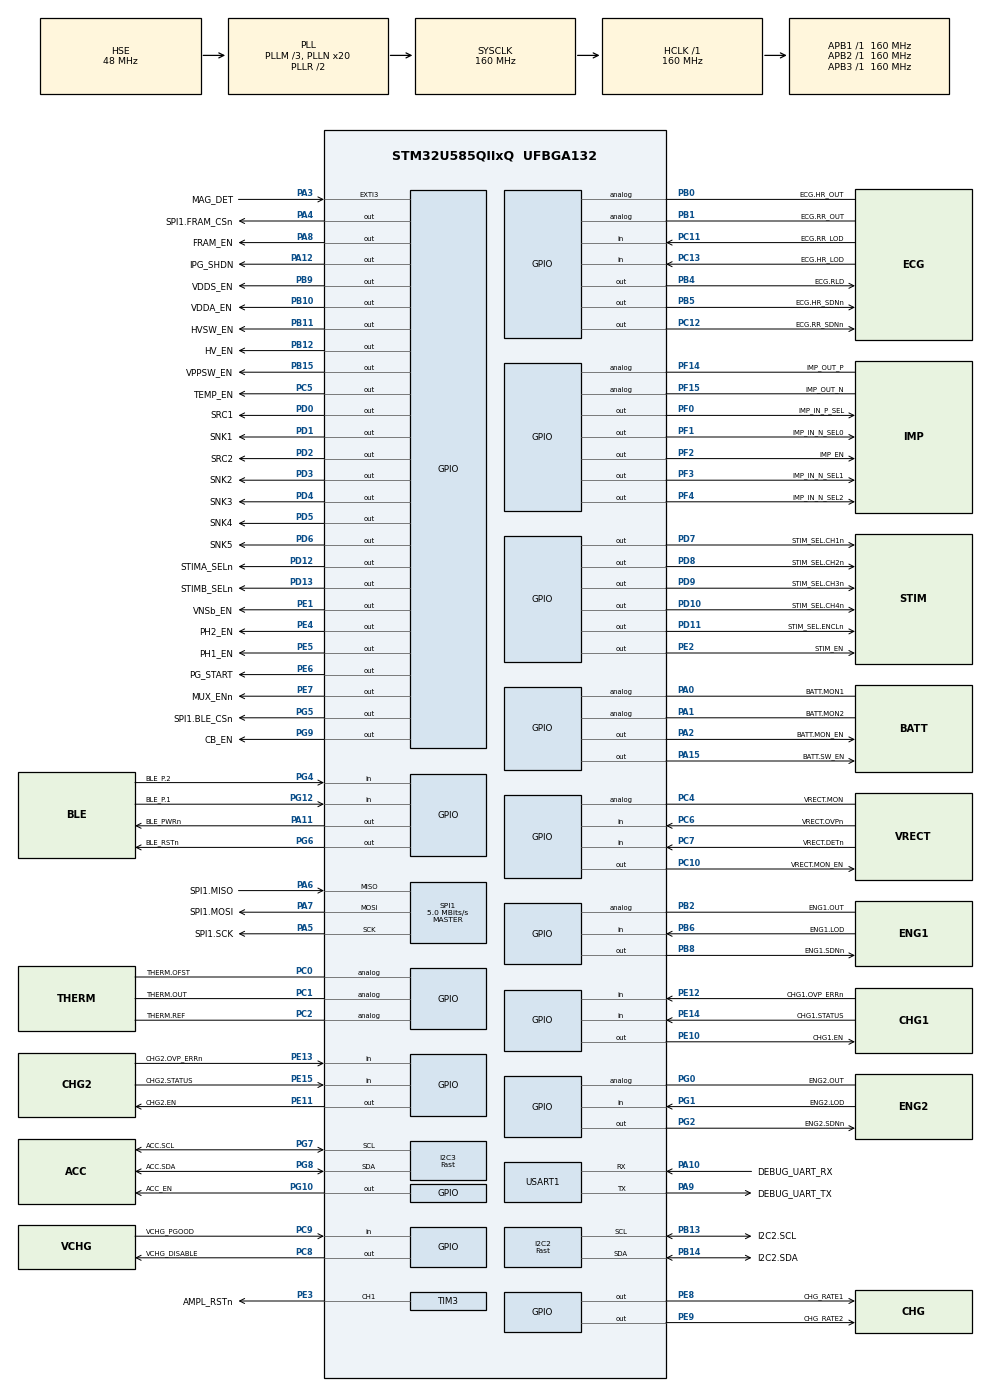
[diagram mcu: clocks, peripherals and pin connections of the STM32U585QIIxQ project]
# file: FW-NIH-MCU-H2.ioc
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ADC1.Channel-0\#ChannelRegularConversion=ADC_CHANNEL_VREFINT
ADC1.Channel-10\#ChannelRegularConversion=ADC_CHANNEL_VREFINT
ADC1.ClockPrescaler=ADC_CLOCK_ASYNC_DIV2
ADC1.ContinuousConvMode=DISABLE
ADC1.ConversionDataManagement=ADC_CONVERSIONDATA_DMA_ONESHOT
ADC1.DiscontinuousConvMode=DISABLE
ADC1.EOCSelection=ADC_EOC_SINGLE_CONV
ADC1.EnableInjectedConversion=DISABLE
ADC1.EnableRegularConversion=ENABLE
ADC1.ExternalTrigConv=ADC_EXTERNALTRIG_T6_TRGO
ADC1.MonitoredBy-0\#ChannelRegularConversion=__NULL
ADC1.MonitoredBy-10\#ChannelRegularConversion=__NULL
ADC1.NbrOfConversion=2
ADC1.NbrOfConversionFlag=1
ADC1.OffsetNumber-0\#ChannelRegularConversion=ADC_OFFSET_NONE
ADC1.OffsetNumber-10\#ChannelRegularConversion=ADC_OFFSET_NONE
ADC1.Rank-0\#ChannelRegularConversion=1
ADC1.Rank-10\#ChannelRegularConversion=2
ADC1.Resolution=ADC_RESOLUTION_12B
ADC1.SamplingTime-0\#ChannelRegularConversion=ADC_SAMPLETIME_5CYCLE
ADC1.SamplingTime-10\#ChannelRegularConversion=ADC_SAMPLETIME_5CYCLE
ADC1.master=1
ADC4.Channel1=true
ADC4.Channell1=false
ADC4.ClockPrescaler=ADC_CLOCK_ASYNC_DIV2
ADC4.ContinuousConvMode=DISABLE
ADC4.EOCSelection=ADC_EOC_SINGLE_CONV
ADC4.ExternalTrigConv=ADC4_EXTERNALTRIG_T15_TRGO
ADC4.NbrOfConversion=1
ADC4.NbrOfConversionFlag=0
ADC4.SamplingTimeCommon1=ADC4_SAMPLETIME_7CYCLES_5
ADC4.SamplingTimeCommon2=ADC4_SAMPLETIME_1CYCLE_5
ADC4.SelectedChannel=ADC_CHANNEL_VREFINT
CORTEX_M33_NS.userName=CORTEX_M33
CRC.CRCLength=CRC_POLYLENGTH_16B
CRC.DefaultInitValueUse=DEFAULT_INIT_VALUE_DISABLE
CRC.DefaultPolynomialUse=DEFAULT_POLYNOMIAL_DISABLE
CRC.GeneratingPolynomial=X12+X5+X0
CRC.InitValue=0xFFFF
GPDMA1.CIRCULARMODE_GPDMACH0=DISABLE
GPDMA1.CIRCULARMODE_GPDMACH1=DISABLE
GPDMA1.DESTDATAWIDTH_GPDMACH0=DMA_DEST_DATAWIDTH_WORD
GPDMA1.DESTDATAWIDTH_GPDMACH1=DMA_DEST_DATAWIDTH_WORD
GPDMA1.DESTINC_GPDMACH0=DMA_DINC_INCREMENTED
GPDMA1.DESTINC_GPDMACH1=DMA_DINC_INCREMENTED
GPDMA1.IPHANDLE_GPDMACH0-SIMPLEREQUEST_GPDMACH0=__NULL
GPDMA1.IPHANDLE_GPDMACH1-SIMPLEREQUEST_GPDMACH1=__NULL
GPDMA1.LINKALLOCATEDPORT_CIRCULAR_GPDMACH1=DMA_LINK_ALLOCATED_PORT1
GPDMA1.REQUEST_GPDMACH0=GPDMA1_REQUEST_ADC1
GPDMA1.REQUEST_GPDMACH1=GPDMA1_REQUEST_ADC4
GPDMA1.SRCDATAWIDTH_GPDMACH0=DMA_SRC_DATAWIDTH_WORD
GPDMA1.SRCDATAWIDTH_GPDMACH1=DMA_SRC_DATAWIDTH_WORD
GPDMA1.TRANSFERALLOCATEDPORTDEST_GPDMACH1=DMA_DEST_ALLOCATED_PORT1
GPDMA1.TRANSFERALLOCATEDPORTSRC_GPDMACH1=DMA_SRC_ALLOCATED_PORT1
HASH.DataType=HASH_DATATYPE_8B
HASH.SecureHashAlgorithmType=SHA256
I2C2.I2C_Speed_Mode=I2C_Fast
I2C2.Timing=0x00F07BFF
I2C3.I2C_Coeff_DF=0
I2C3.I2C_Speed_Mode=I2C_Fast
I2C3.Timing=0x00F07BFF
IWDG.EWI=100
IWDG.Prescaler=IWDG_PRESCALER_32
IWDG.Reload=1000
IWDG.Window=4095
LPTIM1.ClockPrescaler=LPTIM_PRESCALER_DIV128
LPTIM1.Period=60*256
LPTIM1.RepetitionCounter=60-1
LPTIM1.UpdateMode=LPTIM_UPDATE_ENDOFPERIOD
LPTIM2.ClockPrescaler=LPTIM_PRESCALER_DIV128
LPTIM2.Period=1*256
LPTIM2.RepetitionCounter=1-1
LPTIM2.UpdateMode=LPTIM_UPDATE_ENDOFPERIOD
LPTIM3.ClockPrescaler=LPTIM_PRESCALER_DIV128
LPTIM3.Period=60*256
LPTIM3.RepetitionCounter=1-1
LPTIM4.ClockPrescaler=LPTIM_PRESCALER_DIV128
LPTIM4.Period=256/2
LPTIM4.RepetitionCounter=1-1
Mcu.Family=STM32U5
Mcu.Name=STM32U585QIIxQ
Mcu.Package=UFBGA132
NVIC.ADC1_IRQn=true\:0\:0\:false\:false\:true\:true\:true\:true
NVIC.ADC4_IRQn=true\:0\:0\:false\:false\:true\:true\:true\:true
NVIC.EXTI3_IRQn=true\:0\:0\:false\:false\:true\:true\:true\:true
NVIC.GPDMA1_Channel0_IRQn=true\:0\:0\:false\:false\:true\:false\:true\:true
NVIC.GPDMA1_Channel1_IRQn=true\:0\:0\:false\:false\:true\:false\:true\:true
NVIC.HASH_IRQn=true\:0\:0\:false\:false\:true\:true\:true\:true
NVIC.I2C2_ER_IRQn=true\:0\:0\:false\:false\:true\:true\:true\:true
NVIC.I2C2_EV_IRQn=true\:0\:0\:false\:false\:true\:true\:true\:true
NVIC.I2C3_ER_IRQn=true\:0\:0\:false\:false\:true\:true\:true\:true
NVIC.I2C3_EV_IRQn=true\:0\:0\:false\:false\:true\:true\:true\:true
NVIC.ICACHE_IRQn=true\:0\:0\:false\:false\:true\:true\:true\:true
NVIC.IWDG_IRQn=true\:0\:0\:false\:false\:true\:true\:true\:true
NVIC.LPTIM1_IRQn=true\:0\:0\:false\:false\:true\:true\:true\:true
NVIC.LPTIM2_IRQn=true\:0\:0\:false\:false\:true\:true\:true\:true
NVIC.LPTIM3_IRQn=true\:0\:0\:false\:false\:true\:true\:true\:true
NVIC.LPTIM4_IRQn=true\:0\:0\:false\:false\:true\:true\:true\:true
NVIC.PKA_IRQn=true\:0\:0\:false\:false\:true\:true\:true\:true
NVIC.PriorityGroup=NVIC_PRIORITYGROUP_4
NVIC.RNG_IRQn=true\:0\:0\:false\:false\:true\:true\:true\:true
NVIC.RTC_IRQn=true\:0\:0\:false\:false\:true\:true\:true\:true
NVIC.SPI1_IRQn=true\:0\:0\:false\:false\:true\:true\:true\:true
NVIC.TIM15_IRQn=true\:0\:0\:false\:false\:true\:true\:true\:true
NVIC.TIM3_IRQn=true\:0\:0\:true\:false\:true\:true\:true\:true
NVIC.TIM4_IRQn=true\:0\:0\:false\:false\:true\:true\:true\:true
NVIC.TIM5_IRQn=true\:0\:0\:false\:false\:true\:true\:true\:true
NVIC.TIM6_IRQn=true\:0\:0\:false\:false\:true\:true\:true\:true
NVIC.USART1_IRQn=true\:0\:0\:false\:false\:true\:true\:true\:true
PA0.GPIO_Label=BATT.MON1
PA0.Signal=SharedAnalog_PA0
PA1.GPIO_Label=BATT.MON2
PA1.Signal=SharedAnalog_PA1
PA10.GPIO_Label=DEBUG_UART_RX
PA10.Mode=Asynchronous
PA10.Signal=USART1_RX
PA11.GPIO_Label=BLE_PWRn
PA11.GPIO_PuPd=GPIO_NOPULL
PA11.GPIO_Speed=GPIO_SPEED_FREQ_VERY_HIGH
PA11.PinState=GPIO_PIN_SET
PA11.Signal=GPIO_Output
PA12.GPIO_Label=IPG_SHDN
PA12.Signal=GPIO_Output
PA13\ (JTMS/SWDIO).GPIO_Label=SWDIO
PA13\ (JTMS/SWDIO).Mode=Trace_Asynchronous_SW
PA13\ (JTMS/SWDIO).Signal=DEBUG_JTMS-SWDIO
PA14\ (JTCK/SWCLK).GPIO_Label=SWCLK
PA14\ (JTCK/SWCLK).Mode=Trace_Asynchronous_SW
PA14\ (JTCK/SWCLK).Signal=DEBUG_JTCK-SWCLK
PA15\ (JTDI).GPIO_Label=BATT.SW_EN 
PA15\ (JTDI).GPIO_PuPd=GPIO_PULLUP
PA15\ (JTDI).PinState=GPIO_PIN_SET
PA15\ (JTDI).Signal=GPIO_Output
PA2.GPIO_Label=BATT.MON_EN
PA2.Signal=GPIO_Output
PA3.GPIO_Label=MAG_DET
PA3.GPIO_ModeDefaultEXTI=GPIO_MODE_IT_RISING_FALLING
PA3.Signal=GPXTI3
PA4.GPIO_Label=SPI1.FRAM_CSn
PA4.Signal=GPIO_Output
PA5.GPIO_Label=SPI1.SCK
PA5.Mode=Full_Duplex_Master
PA5.Signal=SPI1_SCK
PA6.GPIO_Label=SPI1.MISO 
PA6.Mode=Full_Duplex_Master
PA6.Signal=SPI1_MISO
PA7.GPIO_Label=SPI1.MOSI
PA7.Mode=Full_Duplex_Master
PA7.Signal=SPI1_MOSI
PA8.GPIO_Label=FRAM_EN
PA8.GPIO_PuPd=GPIO_PULLUP
PA8.GPIO_Speed=GPIO_SPEED_FREQ_VERY_HIGH
PA8.Signal=GPIO_Output
PA9.GPIO_Label=DEBUG_UART_TX
PA9.Mode=Asynchronous
PA9.Signal=USART1_TX
PB0.GPIO_Label=ECG.HR_OUT
PB0.Signal=SharedAnalog_PB0
PB1.GPIO_Label=ECG.RR_OUT
PB1.Signal=SharedAnalog_PB1
PB10.GPIO_Label=VDDA_EN
PB10.Signal=GPIO_Output
PB11.GPIO_Label=HVSW_EN
PB11.Signal=GPIO_Output
PB12.GPIO_Label=HV_EN
PB12.Signal=GPIO_Output
PB13.GPIO_Label=I2C2.SCL
PB13.GPIO_Pu=GPIO_PULLUP
PB13.GPIO_Speed=GPIO_SPEED_FREQ_LOW
PB13.Mode=I2C
PB13.Signal=I2C2_SCL
PB14.GPIO_Label=I2C2.SDA
PB14.GPIO_Pu=GPIO_PULLUP
PB14.GPIO_Speed=GPIO_SPEED_FREQ_LOW
PB14.Mode=I2C
PB14.Signal=I2C2_SDA
PB15.GPIO_Label=VPPSW_EN
PB15.Signal=GPIO_Output
PB2.GPIO_Label=ENG1.OUT
PB2.Signal=SharedAnalog_PB2
PB3\ (JTDO/TRACESWO).GPIO_Label=SWO
PB3\ (JTDO/TRACESWO).Mode=Trace_Asynchronous_SW
PB3\ (JTDO/TRACESWO).Signal=DEBUG_JTDO-SWO
PB4\ (NJTRST).GPIO_Label=ECG.RLD
PB4\ (NJTRST).Signal=GPIO_Output
PB5.GPIO_Label=ECG.HR_SDNn
PB5.Signal=GPIO_Output
PB6.GPIO_Label=ENG1.LOD
PB6.GPIO_PuPd=GPIO_PULLUP
PB6.Signal=GPIO_Input
PB8.GPIO_Label=ENG1.SDNn
PB8.Signal=GPIO_Output
PB9.GPIO_Label=VDDS_EN
PB9.Signal=GPIO_Output
PC0.GPIO_Label=THERM.OFST
PC0.Signal=SharedAnalog_PC0
PC1.GPIO_Label=THERM.OUT
PC1.Signal=SharedAnalog_PC1
PC10.GPIO_Label=VRECT.MON_EN
PC10.Signal=GPIO_Output
PC11.GPIO_Label=ECG.RR_LOD
PC11.GPIO_PuPd=GPIO_PULLUP
PC11.Signal=GPIO_Input
PC12.GPIO_Label=ECG.RR_SDNn
PC12.Signal=GPIO_Output
PC13.GPIO_Label=ECG.HR_LOD
PC13.GPIO_PuPd=GPIO_PULLUP
PC13.Signal=GPIO_Input
PC14-OSC32_IN\ (PC14).Mode=LSE-External-Oscillator
PC14-OSC32_IN\ (PC14).Signal=RCC_OSC32_IN
PC15-OSC32_OUT\ (PC15).Mode=LSE-External-Oscillator
PC15-OSC32_OUT\ (PC15).Signal=RCC_OSC32_OUT
PC2.GPIO_Label=THERM.REF
PC2.Signal=SharedAnalog_PC2
PC4.GPIO_Label=VRECT.MON
PC4.Signal=SharedAnalog_PC4
PC5.GPIO_Label=TEMP_EN
PC5.Signal=GPIO_Output
PC6.GPIO_Label=VRECT.OVPn
PC6.GPIO_PuPd=GPIO_PULLUP
PC6.Signal=GPIO_Input
PC7.GPIO_Label=VRECT.DETn
PC7.GPIO_PuPd=GPIO_PULLUP
PC7.Signal=GPIO_Input
PC8.GPIO_Label=VCHG_DISABLE
PC8.Signal=GPIO_Output
PC9.GPIO_Label=VCHG_PGOOD
PC9.Signal=GPIO_Input
PD0.GPIO_Label=SRC1
PD0.GPIO_PuPd=GPIO_PULLUP
PD0.GPIO_Speed=GPIO_SPEED_FREQ_VERY_HIGH
PD0.Signal=GPIO_Output
PD1.GPIO_Label=SNK1
PD1.GPIO_PuPd=GPIO_PULLUP
PD1.GPIO_Speed=GPIO_SPEED_FREQ_VERY_HIGH
PD1.Signal=GPIO_Output
PD10.GPIO_Label=STIM_SEL.CH4n
PD10.GPIO_PuPd=GPIO_PULLUP
PD10.GPIO_Speed=GPIO_SPEED_FREQ_VERY_HIGH
PD10.Signal=GPIO_Output
PD11.GPIO_Label=STIM_SEL.ENCLn
PD11.GPIO_PuPd=GPIO_PULLUP
PD11.GPIO_Speed=GPIO_SPEED_FREQ_VERY_HIGH
PD11.Signal=GPIO_Output
PD12.GPIO_Label=STIMA_SELn
PD12.GPIO_PuPd=GPIO_PULLUP
PD12.GPIO_Speed=GPIO_SPEED_FREQ_VERY_HIGH
PD12.Signal=GPIO_Output
PD13.GPIO_Label=STIMB_SELn
PD13.GPIO_PuPd=GPIO_PULLUP
PD13.GPIO_Speed=GPIO_SPEED_FREQ_VERY_HIGH
PD13.Signal=GPIO_Output
PD2.GPIO_Label=SRC2
PD2.GPIO_PuPd=GPIO_PULLUP
PD2.GPIO_Speed=GPIO_SPEED_FREQ_VERY_HIGH
PD2.Signal=GPIO_Output
PD3.GPIO_Label=SNK2
PD3.GPIO_PuPd=GPIO_PULLUP
PD3.GPIO_Speed=GPIO_SPEED_FREQ_VERY_HIGH
PD3.Signal=GPIO_Output
PD4.GPIO_Label=SNK3
PD4.GPIO_PuPd=GPIO_PULLUP
PD4.GPIO_Speed=GPIO_SPEED_FREQ_VERY_HIGH
PD4.Signal=GPIO_Output
PD5.GPIO_Label=SNK4
PD5.GPIO_PuPd=GPIO_PULLUP
PD5.GPIO_Speed=GPIO_SPEED_FREQ_VERY_HIGH
PD5.Signal=GPIO_Output
PD6.GPIO_Label=SNK5
PD6.GPIO_PuPd=GPIO_PULLUP
PD6.GPIO_Speed=GPIO_SPEED_FREQ_VERY_HIGH
PD6.Signal=GPIO_Output
PD7.GPIO_Label=STIM_SEL.CH1n
PD7.GPIO_PuPd=GPIO_PULLUP
PD7.GPIO_Speed=GPIO_SPEED_FREQ_VERY_HIGH
PD7.Signal=GPIO_Output
PD8.GPIO_Label=STIM_SEL.CH2n
PD8.GPIO_PuPd=GPIO_PULLUP
PD8.GPIO_Speed=GPIO_SPEED_FREQ_VERY_HIGH
PD8.Signal=GPIO_Output
PD9.GPIO_Label=STIM_SEL.CH3n
PD9.GPIO_PuPd=GPIO_PULLUP
PD9.GPIO_Speed=GPIO_SPEED_FREQ_VERY_HIGH
PD9.Signal=GPIO_Output
PE1.GPIO_Label=VNSb_EN
PE1.GPIO_PuPd=GPIO_PULLUP
PE1.Signal=GPIO_Output
PE10.GPIO_Label=CHG1.EN 
PE10.Signal=GPIO_Output
PE11.GPIO_Label=CHG2.EN 
PE11.Signal=GPIO_Output
PE12.GPIO_Label=CHG1.OVP_ERRn
PE12.GPIO_PuPd=GPIO_PULLUP
PE12.Signal=GPIO_Input
PE13.GPIO_Label=CHG2.OVP_ERRn
PE13.GPIO_PuPd=GPIO_PULLUP
PE13.Signal=GPIO_Input
PE14.GPIO_Label=CHG1.STATUS
PE14.GPIO_PuPd=GPIO_PULLUP
PE14.Signal=GPIO_Input
PE15.GPIO_Label=CHG2.STATUS 
PE15.GPIO_PuPd=GPIO_PULLUP
PE15.Signal=GPIO_Input
PE2.GPIO_Label=STIM_EN
PE2.GPIO_PuPd=GPIO_PULLUP
PE2.Signal=GPIO_Output
PE3.GPIO_Label=AMPL_RSTn
PE3.GPIO_PuPd=GPIO_PULLUP
PE3.GPIO_Speed=GPIO_SPEED_FREQ_VERY_HIGH
PE3.Signal=S_TIM3_CH1
PE4.GPIO_Label=PH2_EN
PE4.GPIO_PuPd=GPIO_NOPULL
PE4.Signal=GPIO_Output
PE5.GPIO_Label=PH1_EN
PE5.GPIO_PuPd=GPIO_NOPULL
PE5.PinState=GPIO_PIN_SET
PE5.Signal=GPIO_Output
PE6.GPIO_Label=PG_START
PE6.GPIO_PuPd=GPIO_NOPULL
PE6.PinState=GPIO_PIN_SET
PE6.Signal=GPIO_Output
PE7.GPIO_Label=MUX_ENn
PE7.Signal=GPIO_Output
PE8.GPIO_Label=CHG_RATE1
PE8.Signal=GPIO_Output
PE9.GPIO_Label=CHG_RATE2
PE9.Signal=GPIO_Output
PF0.GPIO_Label=IMP_IN_P_SEL
PF0.GPIO_PuPd=GPIO_PULLUP
PF0.GPIO_Speed=GPIO_SPEED_FREQ_VERY_HIGH
PF0.Signal=GPIO_Output
PF1.GPIO_Label=IMP_IN_N_SEL0
PF1.GPIO_PuPd=GPIO_PULLUP
PF1.GPIO_Speed=GPIO_SPEED_FREQ_VERY_HIGH
PF1.Signal=GPIO_Output
PF14.GPIO_Label=IMP_OUT_P
PF14.Signal=SharedAnalog_PF14
PF15.GPIO_Label=IMP_OUT_N
PF15.Signal=SharedAnalog_PF15
PF2.GPIO_Label=IMP_EN
PF2.GPIO_PuPd=GPIO_PULLUP
PF2.GPIO_Speed=GPIO_SPEED_FREQ_LOW
PF2.Signal=GPIO_Output
PF3.GPIO_Label=IMP_IN_N_SEL1
PF3.GPIO_PuPd=GPIO_PULLUP
PF3.GPIO_Speed=GPIO_SPEED_FREQ_VERY_HIGH
PF3.Signal=GPIO_Output
PF4.GPIO_Label=IMP_IN_N_SEL2
PF4.GPIO_PuPd=GPIO_PULLUP
PF4.GPIO_Speed=GPIO_SPEED_FREQ_VERY_HIGH
PF4.Signal=GPIO_Output
PG0.GPIO_Label=ENG2.OUT
PG0.Signal=SharedAnalog_PG0
PG1.GPIO_Label=ENG2.LOD
PG1.GPIO_PuPd=GPIO_PULLUP
PG1.Signal=GPIO_Input
PG10.GPIO_Label=ACC_EN
PG10.Signal=GPIO_Output
PG12.GPIO_Label=BLE_P.1
PG12.GPIO_PuPd=GPIO_PULLUP
PG12.Signal=GPIO_Input
PG2.GPIO_Label=ENG2.SDNn
PG2.Signal=GPIO_Output
PG4.GPIO_Label=BLE_P.2
PG4.GPIO_PuPd=GPIO_PULLUP
PG4.Signal=GPIO_Input
PG5.GPIO_Label=SPI1.BLE_CSn
PG5.Signal=GPIO_Output
PG6.GPIO_Label=BLE_RSTn
PG6.GPIO_ModeDefaultOutputPP=GPIO_MODE_OUTPUT_OD
PG6.GPIO_PuPd=GPIO_NOPULL
PG6.Signal=GPIO_Output
PG7.GPIO_Label=ACC.SCL
PG7.GPIO_Speed=GPIO_SPEED_FREQ_VERY_HIGH
PG7.Mode=I2C
PG7.Signal=I2C3_SCL
PG8.GPIO_Label=ACC.SDA
PG8.GPIO_Speed=GPIO_SPEED_FREQ_VERY_HIGH
PG8.Mode=I2C
PG8.Signal=I2C3_SDA
PG9.GPIO_Label=CB_EN
PG9.PinState=GPIO_PIN_SET
PG9.Signal=GPIO_Output
PH0-OSC_IN\ (PH0).Mode=HSE-External-Oscillator
PH0-OSC_IN\ (PH0).Signal=RCC_OSC_IN
PH1-OSC_OUT\ (PH1).Mode=HSE-External-Oscillator
PH1-OSC_OUT\ (PH1).Signal=RCC_OSC_OUT
PWR.PowerMode=PWR_SMPS_SUPPLY
PWR.pwrPrivilege=PWR_PRIVILEGE_NO
ProjectManager.HeapSize=0x200
ProjectManager.StackSize=0x400
ProjectManager.TargetToolchain=STM32CubeIDE
RCC.ADCCLockSelection=RCC_ADCDACCLKSOURCE_PLL2
RCC.ADCFreq_Value=10000000
RCC.AHBFreq_Value=160000000
RCC.APB1Freq_Value=160000000
RCC.APB1TimFreq_Value=160000000
RCC.APB2Freq_Value=160000000
RCC.APB2TimFreq_Value=160000000
RCC.APB3Freq_Value=160000000
RCC.CortexFreq_Value=160000000
RCC.EPOD_VALUE=48000000
RCC.HCLKFreq_Value=160000000
RCC.HSE_VALUE=48000000
RCC.HSI48_VALUE=48000000
RCC.HSI_VALUE=16000000
RCC.LPTIM1CLockSelectionVirtual=RCC_LPTIM1CLKSOURCE_LSE
RCC.LPTIM2CLockSelectionVirtual=RCC_LPTIM2CLKSOURCE_LSE
RCC.LPTIM3CLockSelectionVirtual=RCC_LPTIM34CLKSOURCE_LSE
RCC.LSIDIV_VALUE=32000
RCC.MSI_VALUE=4000000
RCC.PLL2M=12
RCC.PLL2N=40
RCC.PLL2R=16
RCC.PLL2Source=RCC_PLLSOURCE_HSE
RCC.PLLM=3
RCC.PLLN=20
RCC.PLLSourceVirtual=RCC_PLLSOURCE_HSE
RCC.RTCClockSelection=RCC_RTCCLKSOURCE_LSE
RCC.SYSCLKFreq_VALUE=160000000
RCC.SYSCLKSource=RCC_SYSCLKSOURCE_PLLCLK
RCC.USBFreq_Value=48000000
RCC.VCOOutputFreq_Value=320000000
RTC.WakeUpAutoClr=0
RTC.WakeUpClock-WakeUp=RTC_WAKEUPCLOCK_CK_SPRE_16BITS
RTC.WakeUpCounter-WakeUp=60-1
RTC.WeekDay=RTC_WEEKDAY_SUNDAY
RTC.Year=23
SH.S_TIM3_CH1.0=TIM3_CH1,PWM Generation1 CH1
SH.SharedAnalog_PA0.0=GPIO_Analog
SH.SharedAnalog_PA0.1=ADC1_IN5
SH.SharedAnalog_PA1.0=GPIO_Analog
SH.SharedAnalog_PA1.1=ADC1_IN6
SH.SharedAnalog_PB0.0=GPIO_Analog
SH.SharedAnalog_PB0.1=ADC1_IN15
SH.SharedAnalog_PB1.0=GPIO_Analog
SH.SharedAnalog_PB1.1=ADC1_IN16
SH.SharedAnalog_PB2.0=GPIO_Analog
SH.SharedAnalog_PB2.1=ADC1_IN17
SH.SharedAnalog_PC0.0=GPIO_Analog
SH.SharedAnalog_PC0.1=ADC4_IN1
SH.SharedAnalog_PC1.0=GPIO_Analog
SH.SharedAnalog_PC1.1=ADC4_IN2
SH.SharedAnalog_PC2.0=GPIO_Analog
SH.SharedAnalog_PC2.1=ADC4_IN3
SH.SharedAnalog_PC4.0=GPIO_Analog
SH.SharedAnalog_PC4.1=ADC4_IN22
SH.SharedAnalog_PF14.0=GPIO_Analog
SH.SharedAnalog_PF14.1=ADC4_IN5
SH.SharedAnalog_PF15.0=GPIO_Analog
SH.SharedAnalog_PF15.1=ADC4_IN6
SH.SharedAnalog_PG0.0=GPIO_Analog
SH.SharedAnalog_PG0.1=ADC4_IN7
SPI1.BaudRatePrescaler=SPI_BAUDRATEPRESCALER_32
SPI1.CalculateBaudRate=5.0 MBits/s
SPI1.DataSize=SPI_DATASIZE_8BIT
SPI1.Direction=SPI_DIRECTION_2LINES
SPI1.Mode=SPI_MODE_MASTER
SPI1.VirtualType=VM_MASTER
TIM15.PeriodNoDither=1000-1
TIM15.Prescaler=16-1
TIM15.TIM_MasterOutputTrigger=TIM_TRGO_UPDATE
TIM3.Channel-Output\ Compare2\ No\ Output=TIM_CHANNEL_2
TIM3.Channel-PWM\ Generation1\ CH1=TIM_CHANNEL_1
TIM3.OC1Preload_PWM=ENABLE
TIM3.OC2Preload=ENABLE
TIM3.OCMode_2=TIM_OCMODE_TOGGLE
TIM3.PeriodNoDither=1000-1
TIM3.Prescaler=160-1
TIM3.PulseNoDither_1=100-1
TIM3.PulseNoDither_2=1
TIM4.Channel-Output\ Compare2\ No\ Output=TIM_CHANNEL_2
TIM4.Channel-PWM\ Generation1\ No\ Output=TIM_CHANNEL_1
TIM4.OC1Preload_PWM=ENABLE
TIM4.OC2Preload=DISABLE
TIM4.OCMode_2=TIM_OCMODE_TOGGLE
TIM4.PeriodNoDither=1000-1
TIM4.Prescaler=160-1
TIM4.PulseNoDither_1=100-1
TIM4.PulseNoDither_2=1
TIM5.Channel-Output\ Compare2\ No\ Output=TIM_CHANNEL_2
TIM5.Channel-PWM\ Generation1\ No\ Output=TIM_CHANNEL_1
TIM5.OC1Preload_PWM=ENABLE
TIM5.OC2Preload=ENABLE
TIM5.OCMode_2=TIM_OCMODE_TOGGLE
TIM5.PeriodNoDither=1000-1
TIM5.Prescaler=160-1
TIM5.PulseNoDither_1=100-1
TIM5.PulseNoDither_2=1
TIM6.PeriodNoDither=1000-1
TIM6.Prescaler=16-1
TIM6.TIM_MasterOutputTrigger=TIM_TRGO_UPDATE
USART1.VirtualMode-Asynchronous=VM_ASYNC
VP_ADC1_Vref_Input.Mode=IN-Vrefint
VP_ADC4_Vref_Input.Mode=IN-Vrefint
VP_CRC_VS_CRC.Mode=CRC_Activate
VP_GPDMA1_VS_GPDMACH0.Mode=SIMPLEREQUEST_GPDMACH0
VP_GPDMA1_VS_GPDMACH1.Mode=SIMPLEREQUEST_GPDMACH1
VP_HASH_VS_HASH.Mode=HASH_Activate
VP_ICACHE_VS_ICACHE.Mode=DefaultMode
VP_IWDG_VS_IWDG.Mode=IWDG_Activate
VP_LPBAMQUEUE_VS_QUEUE.Mode=QUEUEMODE
VP_LPBAM_VS_SIG1.Mode=SmartRun
VP_LPBAM_VS_SIG4.Mode=LPDMA1
VP_LPTIM1_VS_LPTIM_counterModeInternalClock.Mode=Counts__internal_clock_event_00
VP_LPTIM2_VS_LPTIM_counterModeInternalClock.Mode=Counts__internal_clock_event_00
VP_LPTIM3_VS_LPTIM_counterModeInternalClock.Mode=Counts__internal_clock_event_00
VP_LPTIM4_VS_LPTIM_counterModeInternalClock.Mode=Counts__internal_clock_event_00
VP_MEMORYMAP_VS_MEMORYMAP.Mode=CurAppReg
VP_PKA_VS_PKA.Mode=PKA_Activate
VP_PWR_VS_DBSignals.Mode=DisableDeadBatterySignals
VP_PWR_VS_LPOM.Mode=PowerOptimisation
VP_PWR_VS_SECSignals.Mode=Security/Privilege
VP_PWR_Vdda.Mode=isolationVdda
VP_RNG_VS_RNG.Mode=RNG_Activate
VP_RTC_VS_RTC_Activate.Mode=RTC_Enabled
VP_RTC_VS_RTC_Calendar.Mode=RTC_Calendar
VP_RTC_VS_RTC_WakeUp_intern.Mode=WakeUp
VP_TIM15_VS_ClockSourceINT.Mode=Internal
VP_TIM3_VS_ClockSourceINT.Mode=Internal
VP_TIM3_VS_no_output2.Mode=Output Compare2 No Output
VP_TIM4_VS_ClockSourceINT.Mode=Internal
VP_TIM4_VS_no_output1.Mode=PWM Generation1 No Output
VP_TIM4_VS_no_output2.Mode=Output Compare2 No Output
VP_TIM5_VS_ClockSourceINT.Mode=Internal
VP_TIM5_VS_no_output1.Mode=PWM Generation1 No Output
VP_TIM5_VS_no_output2.Mode=Output Compare2 No Output
VP_TIM6_VS_ClockSourceINT.Mode=Enable_Timer
VP_VREFBUF_V_VREFBUF.Mode=HoldMode
VREF+.Signal=VREFBUF_OUT
VREFBUF.VoltageScaling=SYSCFG_VREFBUF_VOLTAGE_SCALE3
board=custom

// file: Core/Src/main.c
/* USER CODE BEGIN Header */
/**
  ******************************************************************************
  * @file           : main.c
  * @brief          : Main program body
  ******************************************************************************
  * @attention
  *
  * Copyright (c) 2024 STMicroelectronics.
  * All rights reserved.
  *
  * This software is licensed under terms that can be found in the LICENSE file
  * in the root directory of this software component.
  * If no LICENSE file comes with this software, it is provided AS-IS.
  *
  ******************************************************************************
  */
/* USER CODE END Header */
#include "main.h"
#include "adc.h"
#include "crc.h"
#include "gpdma.h"
#include "hash.h"
#include "i2c.h"
#include "icache.h"
#include "iwdg.h"
#include "lptim.h"
#include "memorymap.h"
#include "pka.h"
#include "rng.h"
#include "rtc.h"
#include "spi.h"
#include "tim.h"
#include "usart.h"
#include "gpio.h"

/* USER CODE BEGIN Includes */
#include "app_config.h"
/* USER CODE END Includes */

void SystemClock_Config(void);
void PeriphCommonClock_Config(void);
static void SystemPower_Config(void);

int main(void)
{

  /* MCU Configuration--------------------------------------------------------*/

  /* Reset of all peripherals, Initializes the Flash interface and the Systick. */
  HAL_Init();

  /* Configure the System Power */
  SystemPower_Config();

  /* Configure the system clock */
  SystemClock_Config();

  /* Configure the peripherals common clocks */
  PeriphCommonClock_Config();

  /* Initialize all configured peripherals */
  MX_RTC_Init();
  MX_GPIO_Init();
  MX_GPDMA1_Init();
  MX_USART1_UART_Init();
  MX_ADC1_Init();
  MX_ADC4_Init();
  MX_I2C2_Init();
  MX_I2C3_Init();
  MX_SPI1_Init();
  MX_CRC_Init();
  MX_HASH_Init();
  MX_LPTIM1_Init();
  MX_LPTIM2_Init();
  MX_LPTIM3_Init();
  MX_RNG_Init();
  MX_PKA_Init();
  MX_TIM3_Init();
  MX_TIM6_Init();
  MX_TIM15_Init();
  MX_ICACHE_Init();
  MX_IWDG_Init();
  MX_LPTIM4_Init();
  MX_TIM4_Init();
  MX_TIM5_Init();
  /* USER CODE BEGIN 2 */
  app_init();
  /* USER CODE END 2 */

  /* Infinite loop */
  /* USER CODE BEGIN WHILE */
  while (1)
  {
	  app_handler();
    /* USER CODE END WHILE */

  }
}

void SystemClock_Config(void)
{
  RCC_OscInitTypeDef RCC_OscInitStruct = {0};
  RCC_ClkInitTypeDef RCC_ClkInitStruct = {0};

  /** Configure the main internal regulator output voltage
  */
  if (HAL_PWREx_ControlVoltageScaling(PWR_REGULATOR_VOLTAGE_SCALE1) != HAL_OK)
  {
    Error_Handler();
  }

  /** Configure LSE Drive Capability
  */
  HAL_PWR_EnableBkUpAccess();
  __HAL_RCC_LSEDRIVE_CONFIG(BSP_LSE_DRIVE);

  /** Initializes the CPU, AHB and APB buses clocks
  */
  RCC_OscInitStruct.OscillatorType = RCC_OSCILLATORTYPE_HSI48|RCC_OSCILLATORTYPE_LSI
                              |RCC_OSCILLATORTYPE_HSE|RCC_OSCILLATORTYPE_LSE;
  RCC_OscInitStruct.HSEState = RCC_HSE_ON;
  RCC_OscInitStruct.LSEState = RCC_LSE_ON;
  RCC_OscInitStruct.HSI48State = RCC_HSI48_ON;
  RCC_OscInitStruct.LSIState = RCC_LSI_ON;
  RCC_OscInitStruct.LSIDiv = RCC_LSI_DIV1;
  RCC_OscInitStruct.PLL.PLLState = RCC_PLL_ON;
  RCC_OscInitStruct.PLL.PLLSource = RCC_PLLSOURCE_HSE;
  RCC_OscInitStruct.PLL.PLLMBOOST = RCC_PLLMBOOST_DIV4;
  RCC_OscInitStruct.PLL.PLLM = 3;
  RCC_OscInitStruct.PLL.PLLN = 20;
  RCC_OscInitStruct.PLL.PLLP = 2;
  RCC_OscInitStruct.PLL.PLLQ = 2;
  RCC_OscInitStruct.PLL.PLLR = 2;
  RCC_OscInitStruct.PLL.PLLRGE = RCC_PLLVCIRANGE_1;
  RCC_OscInitStruct.PLL.PLLFRACN = 0;
  if (HAL_RCC_OscConfig(&RCC_OscInitStruct) != HAL_OK)
  {
    Error_Handler();
  }

  /** Initializes the CPU, AHB and APB buses clocks
  */
  RCC_ClkInitStruct.ClockType = RCC_CLOCKTYPE_HCLK|RCC_CLOCKTYPE_SYSCLK
                              |RCC_CLOCKTYPE_PCLK1|RCC_CLOCKTYPE_PCLK2
                              |RCC_CLOCKTYPE_PCLK3;
  RCC_ClkInitStruct.SYSCLKSource = RCC_SYSCLKSOURCE_PLLCLK;
  RCC_ClkInitStruct.AHBCLKDivider = RCC_SYSCLK_DIV1;
  RCC_ClkInitStruct.APB1CLKDivider = RCC_HCLK_DIV1;
  RCC_ClkInitStruct.APB2CLKDivider = RCC_HCLK_DIV1;
  RCC_ClkInitStruct.APB3CLKDivider = RCC_HCLK_DIV1;

  if (HAL_RCC_ClockConfig(&RCC_ClkInitStruct, FLASH_LATENCY_4) != HAL_OK)
  {
    Error_Handler();
  }
}

void PeriphCommonClock_Config(void)
{
  RCC_PeriphCLKInitTypeDef PeriphClkInit = {0};

  /** Initializes the common periph clock
  */
  PeriphClkInit.PeriphClockSelection = RCC_PERIPHCLK_ADCDAC;
  PeriphClkInit.AdcDacClockSelection = RCC_ADCDACCLKSOURCE_PLL2;
  PeriphClkInit.PLL2.PLL2Source = RCC_PLLSOURCE_HSE;
  PeriphClkInit.PLL2.PLL2M = 12;
  PeriphClkInit.PLL2.PLL2N = 40;
  PeriphClkInit.PLL2.PLL2P = 2;
  PeriphClkInit.PLL2.PLL2Q = 2;
  PeriphClkInit.PLL2.PLL2R = 16;
  PeriphClkInit.PLL2.PLL2RGE = RCC_PLLVCIRANGE_0;
  PeriphClkInit.PLL2.PLL2FRACN = 0;
  PeriphClkInit.PLL2.PLL2ClockOut = RCC_PLL2_DIVR;
  if (HAL_RCCEx_PeriphCLKConfig(&PeriphClkInit) != HAL_OK)
  {
    Error_Handler();
  }
}

/**
  * @brief Power Configuration
  * @retval None
  */
static void SystemPower_Config(void)
{
  HAL_PWREx_EnableVddIO2();

  /*
   * Disable the internal Pull-Up in Dead Battery pins of UCPD peripheral
   */
  HAL_PWREx_DisableUCPDDeadBattery();

  /*
   * Switch to SMPS regulator instead of LDO
   */
  if (HAL_PWREx_ConfigSupply(PWR_SMPS_SUPPLY) != HAL_OK)
  {
    Error_Handler();
  }
/* USER CODE BEGIN PWR */
  if (__HAL_RCC_PWR_IS_CLK_DISABLED())
      {
        __HAL_RCC_PWR_CLK_ENABLE();
      }
      HAL_PWR_EnableBkUpAccess();

      if ((RCC->BDCR & RCC_BDCR_LSEDRV) != BSP_LSE_DRIVE)
      {
        uint32_t tickstart = HAL_GetTick();

        CLEAR_BIT(RCC->BDCR, RCC_BDCR_LSEON);
        while (READ_BIT(RCC->BDCR, RCC_BDCR_LSERDY) != 0U)
        {
          if ((HAL_GetTick() - tickstart) > LSE_STARTUP_TIMEOUT) { break; }
        }
        MODIFY_REG(RCC->BDCR, RCC_BDCR_LSEDRV, BSP_LSE_DRIVE);
      }

/* USER CODE END PWR */
}

void Error_Handler(void)
{
  __disable_irq();
  while (1)
  {
  }
}
